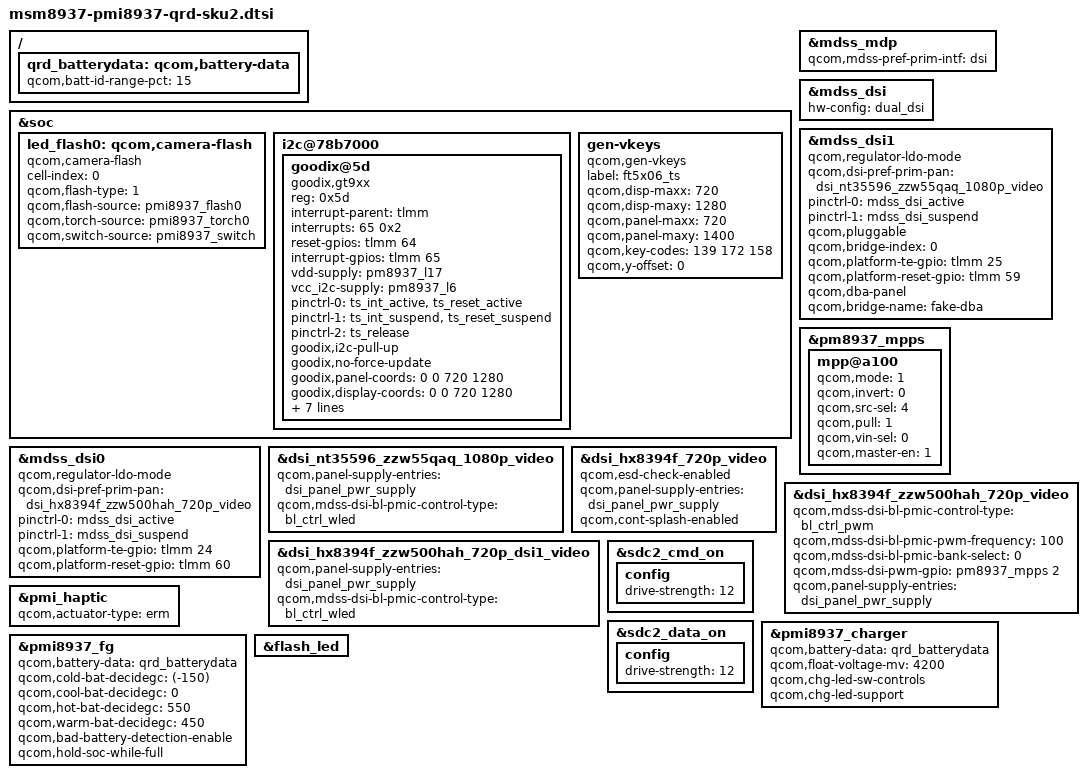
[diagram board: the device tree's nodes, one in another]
/*
 * Copyright (c) 2015-2016, The Linux Foundation. All rights reserved.
 *
 * This program is free software; you can redistribute it and/or modify
 * it under the terms of the GNU General Public License version 2 and
 * only version 2 as published by the Free Software Foundation.
 *
 * This program is distributed in the hope that it will be useful,
 * but WITHOUT ANY WARRANTY; without even the implied warranty of
 * MERCHANTABILITY or FITNESS FOR A PARTICULAR PURPOSE.  See the
 * GNU General Public License for more details.
 */

#include "msm-pmi8937.dtsi"
#include "msm-pm8937.dtsi"
#include "msm8937-qrd.dtsi"
#include "msm8937-mdss-panels.dtsi"
#include "dsi-panel-hx8394f-zzw500hah-720p-dsi1-video.dtsi"
#include "dsi-panel-nt35596-zzw55qaq-1080p-video.dtsi"

&soc {
	led_flash0: qcom,camera-flash {
		cell-index = <0>;
		compatible = "qcom,camera-flash";
		qcom,flash-type = <1>;
		qcom,flash-source = <&pmi8937_flash0>;
		qcom,torch-source = <&pmi8937_torch0>;
		qcom,switch-source = <&pmi8937_switch>;
	};

	i2c@78b7000 {
		status = "ok";
		goodix@5d {
			compatible = "goodix,gt9xx";
			reg = <0x5d>;
			interrupt-parent = <&tlmm>;
			interrupts = <65 0x2>;
			reset-gpios = <&tlmm 64 0x00>;
			interrupt-gpios = <&tlmm 65 0x2002>;
			/*avdd-supply = <&tp_power>;*/
			vdd-supply = <&pm8937_l17>;
			vcc_i2c-supply = <&pm8937_l6>;
			/* pins used by touchscreen */
			pinctrl-names = "pmx_ts_active",
						"pmx_ts_suspend",
						"pmx_ts_release";
			pinctrl-0 = <&ts_int_active &ts_reset_active>;
			pinctrl-1 = <&ts_int_suspend &ts_reset_suspend>;
			pinctrl-2 = <&ts_release>;
			goodix,i2c-pull-up;
			goodix,no-force-update;
			goodix,panel-coords = <0 0 720 1280>;
			goodix,display-coords = <0 0 720 1280>;
			goodix,button-map= <139 172 158>;
			goodix,product-id = "9147";
			goodix,fw_name = "gtp_fw.bin";
			//goodix,enable-power-off; /*modified by kuangjincheng for SLM757 sensor failure on 2016-12-09*/ 
			goodix,cfg-data0 = [
				00 D0 02 00 05 0A 35 01
				01 08 28 05 50 32 03 05
				00 00 00 00 00 00 00 18
				1A 1E 14 89 29 0A 17 15
				31 0D 00 00 01 9B 03 25
				00 00 00 00 00 00 00 32
				00 00 00 0F 36 94 C5 02
				07 00 00 04 9A 11 00 7B
				16 00 65 1C 00 50 25 00
				43 2F 00 43 18 30 48 00
				F0 4A 3A FF FF 27 00 00
				00 00 00 00 00 00 00 00
				00 00 00 00 00 00 00 00
				00 00 00 00 00 00 00 00
				08 0A 0C 0E 10 12 14 16
				18 1A 00 00 00 00 1F FF
				FF FF FF FF FF FF FF FF
				FF FF FF FF FF FF 0E 0C
				0A 08 06 05 04 02 00 1D
				1E 1F 20 22 24 28 29 2A
				00 00 00 00 00 00 00 00
				FF FF FF FF FF FF FF FF
				FF FF FF FF FF FF FF FF
				CC 01];
			goodix,have-touch-key;
			goodix,driver-send-cfg;
		};
		/*focaltech@38 {
			compatible = "focaltech,5x06";
			reg = <0x38>;
			interrupt-parent = <&tlmm>;
			interrupts = <65 0x2>;
			vdd-supply = <&pm8937_l10>;
			vcc_i2c-supply = <&pm8937_l5>;
			// pins used by touchscreen 
			pinctrl-names = "pmx_ts_active",
						"pmx_ts_suspend",
						"pmx_ts_release";
			pinctrl-0 = <&ts_int_active &ts_reset_active>;
			pinctrl-1 = <&ts_int_suspend &ts_reset_suspend>;
			pinctrl-2 = <&ts_release>;
			focaltech,name = "ft5436";
			focaltech,family-id = <0x06>;
			focaltech,reset-gpio = <&tlmm 64 0x0>;
			focaltech,irq-gpio = <&tlmm 65 0x2008>;
			focaltech,display-coords = <0 0 720 1280>;
			focaltech,panel-coords = <0 0 720 1400>;
			focaltech,button-map= <139 102 158>;
			focaltech,no-force-update;
			focaltech,i2c-pull-up;
			focaltech,group-id = <1>;
			focaltech,hard-reset-delay-ms = <20>;
			focaltech,soft-reset-delay-ms = <200>;
			focaltech,num-max-touches = <5>;
			focaltech,fw-delay-aa-ms = <30>;
			focaltech,fw-delay-55-ms = <30>;
			focaltech,fw-upgrade-id1 = <0x79>;
			focaltech,fw-upgrade-id2 = <0x08>;
			focaltech,fw-delay-readid-ms = <10>;
			focaltech,fw-delay-era-flsh-ms = <2000>;
			focaltech,fw-auto-cal;
			focaltech,ignore-id-check;
			//Underlying clocks used by secure touch
			clock-names = "iface_clk", "core_clk";
			clocks = <&clock_gcc clk_gcc_blsp1_ahb_clk>,
				<&clock_gcc clk_gcc_blsp1_qup3_i2c_apps_clk>;
		};*/
	};

	gen-vkeys {
		compatible = "qcom,gen-vkeys";
		label = "ft5x06_ts";
		qcom,disp-maxx = <720>;
		qcom,disp-maxy = <1280>;
		qcom,panel-maxx = <720>;
		qcom,panel-maxy = <1400>;
		qcom,key-codes = <139 172 158>;
		qcom,y-offset = <0>;
	};
};

/*************************** Associated with LCD start **************************************/
&mdss_mdp {
	qcom,mdss-pref-prim-intf = "dsi";
};

&mdss_dsi {
	hw-config = "dual_dsi";
	/*hw-config = "single_dsi";*/
};

&mdss_dsi1 {
	/*status = "disabled";*/
	/*mipi dsi regulator mode: dc-dc or ldo*/
	qcom,regulator-ldo-mode;
	qcom,dsi-pref-prim-pan = <&dsi_nt35596_zzw55qaq_1080p_video>;
	pinctrl-names = "mdss_default", "mdss_sleep";
	pinctrl-0 = <&mdss_dsi_active>;
	pinctrl-1 = <&mdss_dsi_suspend>;

	qcom,pluggable;
	qcom,bridge-index = <0>;
	qcom,platform-te-gpio = <&tlmm 25 0>;
	qcom,platform-reset-gpio = <&tlmm 59 0>;
	qcom,dba-panel;
	qcom,bridge-name = "fake-dba";
};
// add by eliot shao 2016.11.1
&pm8937_mpps {
	mpp@a100 {
				/* MPP2 - PA_THERM config */
				qcom,mode = <1>;
				qcom,invert = <0>;
				qcom,src-sel = <4>;
				qcom,pull = <1>;
				qcom,vin-sel = <0>;
				qcom,master-en = <1>;
			};
};
&mdss_dsi0 {
	/*mipi dsi regulator mode: dc-dc or ldo*/
	qcom,regulator-ldo-mode;
	qcom,dsi-pref-prim-pan = <&dsi_hx8394f_zzw500hah_720p_video>;
	pinctrl-names = "mdss_default", "mdss_sleep";
	pinctrl-0 = <&mdss_dsi_active>;
	pinctrl-1 = <&mdss_dsi_suspend>;

	qcom,platform-te-gpio = <&tlmm 24 0>;
	qcom,platform-reset-gpio = <&tlmm 60 0>;
};

&dsi_nt35596_zzw55qaq_1080p_video {
	qcom,panel-supply-entries = <&dsi_panel_pwr_supply>;
	qcom,mdss-dsi-bl-pmic-control-type = "bl_ctrl_wled";
};

&dsi_hx8394f_720p_video {
	qcom,esd-check-enabled;
	qcom,panel-supply-entries = <&dsi_panel_pwr_supply>;
	qcom,cont-splash-enabled;
};

/*added by mickey.shi, 10/19/2016*/
&dsi_hx8394f_zzw500hah_720p_dsi1_video {
	qcom,panel-supply-entries = <&dsi_panel_pwr_supply>;
	 qcom,mdss-dsi-bl-pmic-control-type = "bl_ctrl_wled";
};

/*added by mickey.shi, 10/10/2016*/
&dsi_hx8394f_zzw500hah_720p_video {
	qcom,mdss-dsi-bl-pmic-control-type = "bl_ctrl_pwm";
	qcom,mdss-dsi-bl-pmic-pwm-frequency = <100>;
	qcom,mdss-dsi-bl-pmic-bank-select = <0>;
	qcom,mdss-dsi-pwm-gpio = <&pm8937_mpps 2 0>;
	qcom,panel-supply-entries = <&dsi_panel_pwr_supply>;
};

/*************************** Associated with LCD end **************************************/

&pmi_haptic {
	status = "okay";
	qcom,actuator-type = "erm";
};

&sdc2_cmd_on {
	config {
		drive-strength = <12>;
	};
};

&sdc2_data_on {
	config {
		drive-strength = <12>;
	};
};

/ {
	qrd_batterydata: qcom,battery-data {
		qcom,batt-id-range-pct = <15>;
		#include "batterydata-qrd-sku2-4v35-2590mah.dtsi"
	};
};

&pmi8937_charger {
	qcom,battery-data = <&qrd_batterydata>;
	qcom,float-voltage-mv = <4200>;
	qcom,chg-led-sw-controls;
	qcom,chg-led-support;
	status = "okay";
};

&pmi8937_fg {
	qcom,battery-data = <&qrd_batterydata>;
	qcom,cold-bat-decidegc = <(-150)>;
	qcom,cool-bat-decidegc = <0>;
	qcom,hot-bat-decidegc = <550>;
	qcom,warm-bat-decidegc = <450>;
	qcom,bad-battery-detection-enable;
	qcom,hold-soc-while-full;
};

&flash_led {
	/delete-node/ qcom,flash_1;
	/delete-node/ qcom,torch_1;
};
